# ATSAML22N17A register map
Vendor: Atmel Corporation; Series: SAML22; File version: A
CPU: CM0+ r0p1, little endian, MPU, no FPU, VTOR, 2 interrupt priority bits
Registers are 32-bit, read-write, reset 0x0 unless marked. A register's access mark holds for its fields unless they carry their own. Offsets are from the block's base; [hi:lo] are bit positions; {n}, {i} and the like mark numbered series; 'fields as' and 'values as' point back to an identical list.

## PM — Power Manager
Base 0x40000400; register names take the prefix PM_
0x00 CTRLA 8-bit — Control A
  [2] IORET — I/O Retention
0x01 SLEEPCFG 8-bit reset 0x2 — Sleep Configuration
  [2:0] SLEEPMODE
    0=IDLE0 (CPU clock is OFF); 1=IDLE1 (AHB clock is OFF); 2=IDLE2 (APB clock are OFF); 4=STANDBY (All Clocks are OFF); 5=BACKUP (Only Backup domain is powered ON); 6=OFF (All power domains are powered OFF)
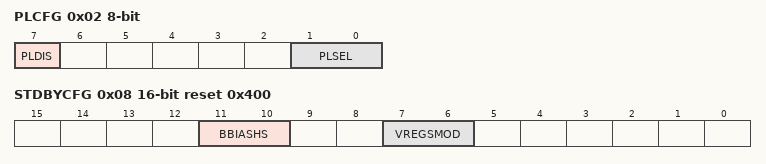
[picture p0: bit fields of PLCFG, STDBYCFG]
0x02 PLCFG 8-bit — Performance Level Configuration
  [7] PLDIS — Performance Level Disable
  [1:0] PLSEL — Performance Level Select
    0=PL0 (Performance Level 0); 1=PL1 (Performance Level 1); 2=PL2 (Performance Level 2)
0x04 INTENCLR 8-bit — Interrupt Enable Clear
  [0] PLRDY wo — Performance Level Interrupt Enable
0x05 INTENSET 8-bit — Interrupt Enable Set
  [0] PLRDY — Performance Level Ready interrupt Enable
0x06 INTFLAG 8-bit — Interrupt Flag Status and Clear
  [0] PLRDY — Performance Level Ready
0x08 STDBYCFG 16-bit reset 0x400 — Standby Configuration
  [11:10] BBIASHS — Back Bias for HMCRAMCHS
  [7:6] VREGSMOD — Voltage Regulator Standby mode
    0=AUTO (Automatic mode); 1=PERFORMANCE (Performance oriented); 2=LP (Low Power oriented)

## PORT — Port Module
Base 0x41006000; register names take the prefix PORT_
{0x0+0x80*i} DIR{i} (i=0..2) — Data Direction
{0x4+0x80*i} DIRCLR{i} (i=0..2) — Data Direction Clear
{0x8+0x80*i} DIRSET{i} (i=0..2) — Data Direction Set
{0xC+0x80*i} DIRTGL{i} (i=0..2) — Data Direction Toggle
{0x10+0x80*i} OUT{i} (i=0..2) — Data Output Value
{0x14+0x80*i} OUTCLR{i} (i=0..2) — Data Output Value Clear
{0x18+0x80*i} OUTSET{i} (i=0..2) — Data Output Value Set
{0x1C+0x80*i} OUTTGL{i} (i=0..2) — Data Output Value Toggle
{0x20+0x80*i} IN{i} (i=0..2) ro — Data Input Value
{0x24+0x80*i} CTRL{i} (i=0..2) — Control
  [31:0] SAMPLING wo — Input Sampling Mode
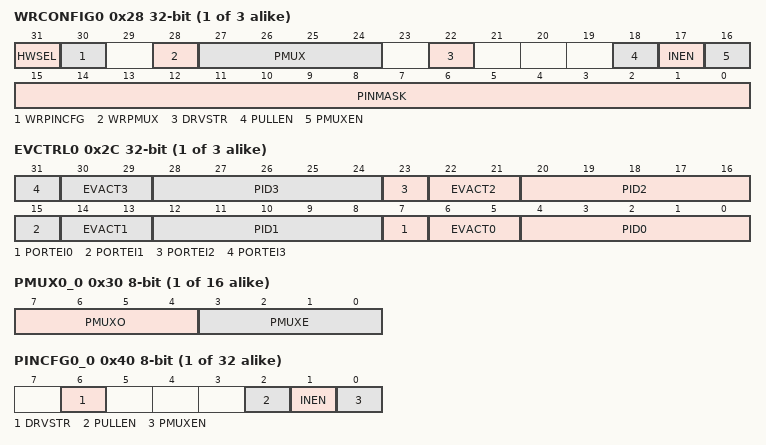
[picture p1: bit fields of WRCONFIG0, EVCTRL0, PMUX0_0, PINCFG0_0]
{0x28+0x80*i} WRCONFIG{i} (i=0..2) wo — Write Configuration
  [31] HWSEL — Half-Word Select
  [30] WRPINCFG — Write PINCFG Registers
  [28] WRPMUX — Write PMUX Registers
  [27:24] PMUX — Peripheral Multiplexing Template
  [22] DRVSTR — Output Driver Strength Selection
  [18] PULLEN — Pull Enable
  [17] INEN — Input Enable
  [16] PMUXEN — Select Peripheral Multiplexer
  [15:0] PINMASK — Pin Mask for Multiple Pin Configuration
{0x2C+0x80*i} EVCTRL{i} (i=0..2) — Event Input Control
  [8n+7] PORTEI{n} (n=0..3) — Port Event Enable Input {n}
  [8n+6:8n+5] EVACT{n} (n=0..3) — Port Event Action {n}
  [8n+4:8n] PID{n} (n=0..3) — Port Event Pin Identifier {n}
{0x30+i} PMUX0_{i} (i=0..15) 8-bit — Peripheral Multiplexing n - Group 0
  [7:4] PMUXO — Peripheral Multiplexing for Odd-Numbered Pin
  [3:0] PMUXE — Peripheral Multiplexing for Even-Numbered Pin
{0x40+i} PINCFG0_{i} (i=0..31) 8-bit — Pin Configuration n - Group 0
  [6] DRVSTR wo — Output Driver Strength Selection
  [2] PULLEN — Pull Enable
  [1] INEN — Input Enable
  [0] PMUXEN — Select Peripheral Multiplexer
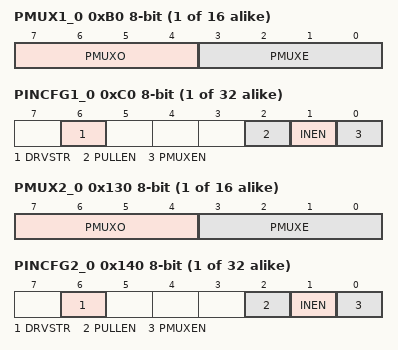
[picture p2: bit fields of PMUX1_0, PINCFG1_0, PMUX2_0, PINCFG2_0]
{0xB0+i} PMUX1_{i} (i=0..15) 8-bit — Peripheral Multiplexing n - Group 1
  fields as PMUX0_0
{0xC0+i} PINCFG1_{i} (i=0..31) 8-bit — Pin Configuration n - Group 1
  fields as PINCFG0_0
{0x130+i} PMUX2_{i} (i=0..15) 8-bit — Peripheral Multiplexing n - Group 2
  fields as PMUX0_0
{0x140+i} PINCFG2_{i} (i=0..31) 8-bit — Pin Configuration n - Group 2
  fields as PINCFG0_0

## RSTC — Reset Controller
Base 0x40000C00; register names take the prefix RSTC_
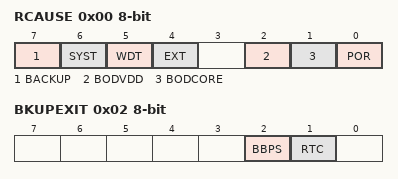
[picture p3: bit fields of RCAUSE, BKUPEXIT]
0x00 RCAUSE 8-bit ro — Reset Cause
  [7] BACKUP — Backup Reset
  [6] SYST — System Reset Request
  [5] WDT — Watchdog Reset
  [4] EXT — External Reset
  [2] BODVDD — Brown Out VDD Detector Reset
  [1] BODCORE — Brown Out CORE Detector Reset
  [0] POR — Power On Reset
0x02 BKUPEXIT 8-bit ro — Backup Exit Source
  [2] BBPS — Battery Backup Power Switch
  [1] RTC — Real Timer Counter Interrupt
